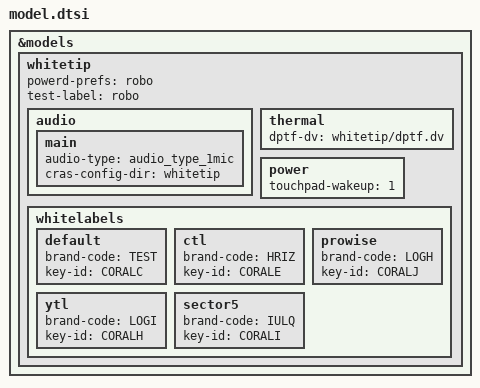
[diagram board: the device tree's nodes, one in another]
/*
 * Copyright 2017 The Chromium OS Authors. All rights reserved.
 *
 * Use of this source code is governed by a BSD-style license that can be
 * found in the LICENSE file.
 */

&models {
	whitetip: whitetip {
		powerd-prefs = "robo";
		test-label = "robo";
		audio {
			main {
				audio-type = <&audio_type_1mic>;
				cras-config-dir = "whitetip";
			};
		};
		thermal {
			dptf-dv = "whitetip/dptf.dv";
		};
		power {
			touchpad-wakeup = "1";
		};
		whitelabels {
			// *default* LOEM
			default {
				brand-code = "TEST";
				key-id = "CORALC";
			};
			ctl {
				brand-code = "HRIZ";
				key-id = "CORALE";
			};
			prowise {
				brand-code = "LOGH";
				key-id = "CORALJ";
			};
			ytl {
				brand-code = "LOGI";
				key-id = "CORALH";
			};
			sector5 {
				brand-code = "IULQ";
				key-id = "CORALI";
			};
			// Following are the brand codes allocated but not yet in used.
			//	brand-code = "TPHN";
			//	brand-code = "URZD";
			//	brand-code = "QTMI";
			//	brand-code = "QHTT";
			//	brand-code = "FGNZ";
			//	brand-code = "JLRH";
		};
	};
};
